AUTOSAR XML (schema 4-2-2)
package /STELLANTIS/EPT/ASWCs
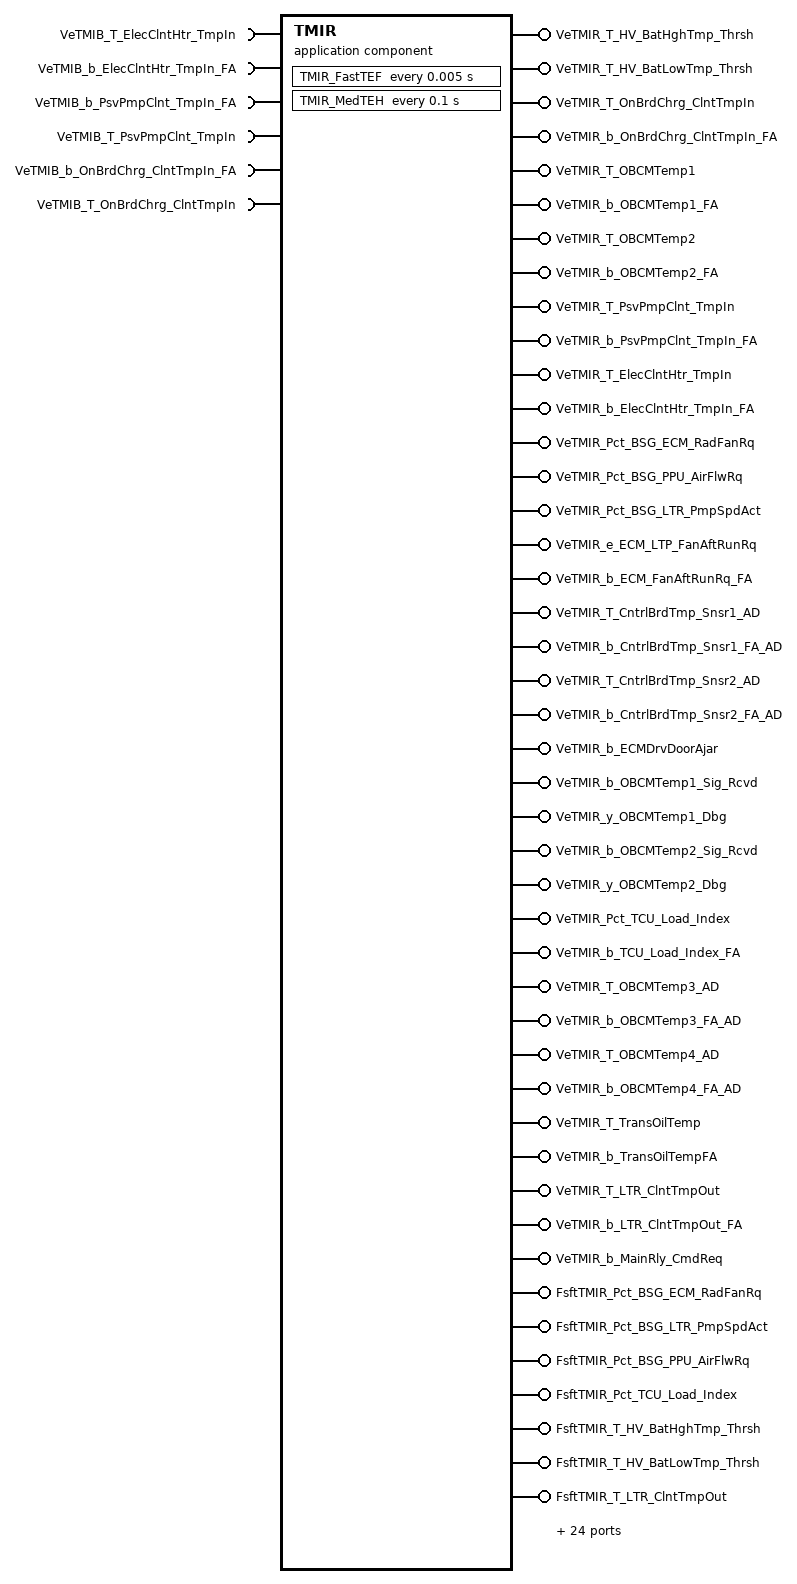
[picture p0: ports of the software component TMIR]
  application sw component type TMIR
    6 x require port, all with nonqueued-receiver-com-spec{data-element=Value, init-value=0}:
      VeTMIB_T_ElecClntHtr_TmpIn: required-interface=VeTMIB_T_ElecClntHtr_TmpIn
      VeTMIB_b_ElecClntHtr_TmpIn_FA: required-interface=VeTMIB_b_ElecClntHtr_TmpIn_FA
      VeTMIB_b_PsvPmpClnt_TmpIn_FA: required-interface=VeTMIB_b_PsvPmpClnt_TmpIn_FA
      VeTMIB_T_PsvPmpClnt_TmpIn: required-interface=VeTMIB_T_PsvPmpClnt_TmpIn
      VeTMIB_b_OnBrdChrg_ClntTmpIn_FA: required-interface=VeTMIB_b_OnBrdChrg_ClntTmpIn_FA
      VeTMIB_T_OnBrdChrg_ClntTmpIn: required-interface=VeTMIB_T_OnBrdChrg_ClntTmpIn
    74 x provide port:
      VeTMIR_T_HV_BatHghTmp_Thrsh: nonqueued-sender-com-spec{data-element=Value, init-value=0}, provided-interface=VeTMIR_T_HV_BatHghTmp_Thrsh
      VeTMIR_T_HV_BatLowTmp_Thrsh: nonqueued-sender-com-spec{data-element=Value, init-value=0}, provided-interface=VeTMIR_T_HV_BatLowTmp_Thrsh
      VeTMIR_T_OnBrdChrg_ClntTmpIn: nonqueued-sender-com-spec{data-element=Value, init-value=0}, provided-interface=VeTMIR_T_OnBrdChrg_ClntTmpIn
      VeTMIR_b_OnBrdChrg_ClntTmpIn_FA: nonqueued-sender-com-spec{data-element=Value, init-value=0}, provided-interface=VeTMIR_b_OnBrdChrg_ClntTmpIn_FA
      VeTMIR_T_OBCMTemp1: nonqueued-sender-com-spec{data-element=Value, init-value=0}, provided-interface=VeTMIR_T_OBCMTemp1
      VeTMIR_b_OBCMTemp1_FA: nonqueued-sender-com-spec{data-element=Value, init-value=0}, provided-interface=VeTMIR_b_OBCMTemp1_FA
      VeTMIR_T_OBCMTemp2: nonqueued-sender-com-spec{data-element=Value, init-value=0}, provided-interface=VeTMIR_T_OBCMTemp2
      VeTMIR_b_OBCMTemp2_FA: nonqueued-sender-com-spec{data-element=Value, init-value=0}, provided-interface=VeTMIR_b_OBCMTemp2_FA
      VeTMIR_T_PsvPmpClnt_TmpIn: nonqueued-sender-com-spec{data-element=Value, init-value=0}, provided-interface=VeTMIR_T_PsvPmpClnt_TmpIn
      VeTMIR_b_PsvPmpClnt_TmpIn_FA: nonqueued-sender-com-spec{data-element=Value, init-value=0}, provided-interface=VeTMIR_b_PsvPmpClnt_TmpIn_FA
      VeTMIR_T_ElecClntHtr_TmpIn: nonqueued-sender-com-spec{data-element=Value, init-value=0}, provided-interface=VeTMIR_T_ElecClntHtr_TmpIn
      VeTMIR_b_ElecClntHtr_TmpIn_FA: nonqueued-sender-com-spec{data-element=Value, init-value=0}, provided-interface=VeTMIR_b_ElecClntHtr_TmpIn_FA
      VeTMIR_Pct_BSG_ECM_RadFanRq: nonqueued-sender-com-spec{data-element=Value, init-value=0}, provided-interface=VeTMIR_Pct_BSG_ECM_RadFanRq
      VeTMIR_Pct_BSG_PPU_AirFlwRq: nonqueued-sender-com-spec{data-element=Value, init-value=0}, provided-interface=VeTMIR_Pct_BSG_PPU_AirFlwRq
      VeTMIR_Pct_BSG_LTR_PmpSpdAct: nonqueued-sender-com-spec{data-element=Value, init-value=0}, provided-interface=VeTMIR_Pct_BSG_LTR_PmpSpdAct
      VeTMIR_e_ECM_LTP_FanAftRunRq: nonqueued-sender-com-spec{data-element=Value, init-value=CeTMIR_e_No_AftRunRequest}, provided-interface=VeTMIR_e_ECM_LTP_FanAftRunRq
      VeTMIR_b_ECM_FanAftRunRq_FA: nonqueued-sender-com-spec{data-element=Value, init-value=0}, provided-interface=VeTMIR_b_ECM_FanAftRunRq_FA
      VeTMIR_T_CntrlBrdTmp_Snsr1_AD: nonqueued-sender-com-spec{data-element=Value, init-value=0}, provided-interface=VeTMIR_T_CntrlBrdTmp_Snsr1_AD
      VeTMIR_b_CntrlBrdTmp_Snsr1_FA_AD: nonqueued-sender-com-spec{data-element=Value, init-value=0}, provided-interface=VeTMIR_b_CntrlBrdTmp_Snsr1_FA_AD
      VeTMIR_T_CntrlBrdTmp_Snsr2_AD: nonqueued-sender-com-spec{data-element=Value, init-value=0}, provided-interface=VeTMIR_T_CntrlBrdTmp_Snsr2_AD
      VeTMIR_b_CntrlBrdTmp_Snsr2_FA_AD: nonqueued-sender-com-spec{data-element=Value, init-value=0}, provided-interface=VeTMIR_b_CntrlBrdTmp_Snsr2_FA_AD
      VeTMIR_b_ECMDrvDoorAjar: nonqueued-sender-com-spec{data-element=Value, init-value=0}, provided-interface=VeTMIR_b_ECMDrvDoorAjar
      VeTMIR_b_OBCMTemp1_Sig_Rcvd: nonqueued-sender-com-spec{data-element=Value, init-value=0}, provided-interface=VeTMIR_b_OBCMTemp1_Sig_Rcvd
      VeTMIR_y_OBCMTemp1_Dbg: nonqueued-sender-com-spec{data-element=Value, init-value=0}, provided-interface=VeTMIR_y_OBCMTemp1_Dbg
      VeTMIR_b_OBCMTemp2_Sig_Rcvd: nonqueued-sender-com-spec{data-element=Value, init-value=0}, provided-interface=VeTMIR_b_OBCMTemp2_Sig_Rcvd
      VeTMIR_y_OBCMTemp2_Dbg: nonqueued-sender-com-spec{data-element=Value, init-value=0}, provided-interface=VeTMIR_y_OBCMTemp2_Dbg
      VeTMIR_Pct_TCU_Load_Index: nonqueued-sender-com-spec{data-element=Value, init-value=0}, provided-interface=VeTMIR_Pct_TCU_Load_Index
      VeTMIR_b_TCU_Load_Index_FA: nonqueued-sender-com-spec{data-element=Value, init-value=0}, provided-interface=VeTMIR_b_TCU_Load_Index_FA
      VeTMIR_T_OBCMTemp3_AD: nonqueued-sender-com-spec{data-element=Value, init-value=0}, provided-interface=VeTMIR_T_OBCMTemp3_AD
      VeTMIR_b_OBCMTemp3_FA_AD: nonqueued-sender-com-spec{data-element=Value, init-value=0}, provided-interface=VeTMIR_b_OBCMTemp3_FA_AD
      VeTMIR_T_OBCMTemp4_AD: nonqueued-sender-com-spec{data-element=Value, init-value=0}, provided-interface=VeTMIR_T_OBCMTemp4_AD
      VeTMIR_b_OBCMTemp4_FA_AD: nonqueued-sender-com-spec{data-element=Value, init-value=0}, provided-interface=VeTMIR_b_OBCMTemp4_FA_AD
      VeTMIR_T_TransOilTemp: nonqueued-sender-com-spec{data-element=Value, init-value=0}, provided-interface=VeTMIR_T_TransOilTemp
      VeTMIR_b_TransOilTempFA: nonqueued-sender-com-spec{data-element=Value, init-value=0}, provided-interface=VeTMIR_b_TransOilTempFA
      VeTMIR_T_LTR_ClntTmpOut: nonqueued-sender-com-spec{data-element=Value, init-value=0}, provided-interface=VeTMIR_T_LTR_ClntTmpOut
      VeTMIR_b_LTR_ClntTmpOut_FA: nonqueued-sender-com-spec{data-element=Value, init-value=0}, provided-interface=VeTMIR_b_LTR_ClntTmpOut_FA
      VeTMIR_b_MainRly_CmdReq: nonqueued-sender-com-spec{data-element=Value, init-value=0}, provided-interface=VeTMIR_b_MainRly_CmdReq
      FsftTMIR_Pct_BSG_ECM_RadFanRq: server-com-spec=FsftTMIR_Pct_BSG_ECM_RadFanRq, provided-interface=FsftTMIR_Pct_BSG_ECM_RadFanRq
      FsftTMIR_Pct_BSG_LTR_PmpSpdAct: server-com-spec=FsftTMIR_Pct_BSG_LTR_PmpSpdAct, provided-interface=FsftTMIR_Pct_BSG_LTR_PmpSpdAct
      FsftTMIR_Pct_BSG_PPU_AirFlwRq: server-com-spec=FsftTMIR_Pct_BSG_PPU_AirFlwRq, provided-interface=FsftTMIR_Pct_BSG_PPU_AirFlwRq
      FsftTMIR_Pct_TCU_Load_Index: server-com-spec=FsftTMIR_Pct_TCU_Load_Index, provided-interface=FsftTMIR_Pct_TCU_Load_Index
      FsftTMIR_T_HV_BatHghTmp_Thrsh: server-com-spec=FsftTMIR_T_HV_BatHghTmp_Thrsh, provided-interface=FsftTMIR_T_HV_BatHghTmp_Thrsh
      FsftTMIR_T_HV_BatLowTmp_Thrsh: server-com-spec=FsftTMIR_T_HV_BatLowTmp_Thrsh, provided-interface=FsftTMIR_T_HV_BatLowTmp_Thrsh
      FsftTMIR_T_LTR_ClntTmpOut: server-com-spec=FsftTMIR_T_LTR_ClntTmpOut, provided-interface=FsftTMIR_T_LTR_ClntTmpOut
      FsftTMIR_T_OBCMTemp{1..4}: server-com-spec=FsftTMIR_T_OBCMTemp{1..4}, provided-interface=FsftTMIR_T_OBCMTemp{1..4}
      FsftTMIR_V_DISPLACEMENT: server-com-spec=FsftTMIR_V_DISPLACEMENT, provided-interface=FsftTMIR_V_DISPLACEMENT
      FsftTMIR_b_ECMDrvDoorAjar: server-com-spec=FsftTMIR_b_ECMDrvDoorAjar, provided-interface=FsftTMIR_b_ECMDrvDoorAjar
      FsftTMIR_e_ECM_LTP_FanAftRun_Rq: server-com-spec=FsftTMIR_e_ECM_LTP_FanAftRun_Rq, provided-interface=FsftTMIR_e_ECM_LTP_FanAftRun_Rq
      FsftTMIR_e_VC_VEH_LINE: server-com-spec=FsftTMIR_e_VC_VEH_LINE, provided-interface=FsftTMIR_e_VC_VEH_LINE
      PokeTMIR_Pct_BSG_ECM_RadFanRq: server-com-spec{operation=PokeTMIR_Pct_BSG_ECM_RadFanRq, queue-length=1}, provided-interface=PokeTMIR_Pct_BSG_ECM_RadFanRq
      PokeTMIR_Pct_BSG_LTR_PmpSpdAct: server-com-spec{operation=PokeTMIR_Pct_BSG_LTR_PmpSpdAct, queue-length=1}, provided-interface=PokeTMIR_Pct_BSG_LTR_PmpSpdAct
      PokeTMIR_Pct_BSG_PPU_AirFlwRq: server-com-spec{operation=PokeTMIR_Pct_BSG_PPU_AirFlwRq, queue-length=1}, provided-interface=PokeTMIR_Pct_BSG_PPU_AirFlwRq
      PokeTMIR_Pct_TCU_Load_Index: server-com-spec{operation=PokeTMIR_Pct_TCU_Load_Index, queue-length=1}, provided-interface=PokeTMIR_Pct_TCU_Load_Index
      PokeTMIR_T_HV_BatHghTmp_Thrsh: server-com-spec{operation=PokeTMIR_T_HV_BatHghTmp_Thrsh, queue-length=1}, provided-interface=PokeTMIR_T_HV_BatHghTmp_Thrsh
      PokeTMIR_T_HV_BatLowTmp_Thrsh: server-com-spec{operation=PokeTMIR_T_HV_BatLowTmp_Thrsh, queue-length=1}, provided-interface=PokeTMIR_T_HV_BatLowTmp_Thrsh
      PokeTMIR_T_LTR_ClntTmpOut: server-com-spec{operation=PokeTMIR_T_LTR_ClntTmpOut, queue-length=1}, provided-interface=PokeTMIR_T_LTR_ClntTmpOut
      PokeTMIR_T_OBCMTemp{1..4}: server-com-spec{operation=PokeTMIR_T_OBCMTemp{1..4}, queue-length=1}, provided-interface=PokeTMIR_T_OBCMTemp{1..4}
      PokeTMIR_T_PIM_CntrlBoardTmp1: server-com-spec{operation=PokeTMIR_T_PIM_CntrlBoardTmp1, queue-length=1}, provided-interface=PokeTMIR_T_PIM_CntrlBoardTmp1
      PokeTMIR_T_PIM_CntrlBoardTmp2: server-com-spec{operation=PokeTMIR_T_PIM_CntrlBoardTmp2, queue-length=1}, provided-interface=PokeTMIR_T_PIM_CntrlBoardTmp2
      PokeTMIR_T_TransOilTemp: server-com-spec{operation=PokeTMIR_T_TransOilTemp, queue-length=1}, provided-interface=PokeTMIR_T_TransOilTemp
      PokeTMIR_V_DISPLACEMENT: server-com-spec{operation=PokeTMIR_V_DISPLACEMENT, queue-length=1}, provided-interface=PokeTMIR_V_DISPLACEMENT
      PokeTMIR_b_MainRly_CmdReq: server-com-spec{operation=PokeTMIR_b_MainRly_CmdReq, queue-length=1}, provided-interface=PokeTMIR_b_MainRly_CmdReq
      PokeTMIR_e_ECMDrvDoorAjar: server-com-spec{operation=PokeTMIR_e_ECMDrvDoorAjar, queue-length=1}, provided-interface=PokeTMIR_e_ECMDrvDoorAjar
      PokeTMIR_e_ECM_LTP_FanAftRun_Rq: server-com-spec{operation=PokeTMIR_e_ECM_LTP_FanAftRun_Rq, queue-length=1}, provided-interface=PokeTMIR_e_ECM_LTP_FanAftRun_Rq
      PokeTMIR_e_VC_VEH_LINE: server-com-spec{operation=PokeTMIR_e_VC_VEH_LINE, queue-length=1}, provided-interface=PokeTMIR_e_VC_VEH_LINE
      TmotTMIR_b_ECMDrvDoorAjar: server-com-spec=TmotTMIR_b_ECMDrvDoorAjar, provided-interface=TmotTMIR_b_ECMDrvDoorAjar
      TmotTMIR_b_OBCMTemp1: server-com-spec=TmotTMIR_b_OBCMTemp1, provided-interface=TmotTMIR_b_OBCMTemp1
      TmotTMIR_b_OBCMTemp2: server-com-spec=TmotTMIR_b_OBCMTemp2, provided-interface=TmotTMIR_b_OBCMTemp2
    behavior IB_TMIR: data-type-mapping=msADTtoIDTMapping, handle-termination-and-restart=NO-SUPPORT
      timing event Event_FastTEF: start-on-event=TMIR_FastTEF, period=0.005
      timing event Event_MedTEH: start-on-event=TMIR_MedTEH, period=0.1
      37 x operation invoked event:
        Event_FsftTMIR_Pct_BSG_ECM_RadFanRq: start-on-event=FsftTMIR_Pct_BSG_ECM_RadFanRq, operation=FsftTMIR_Pct_BSG_ECM_RadFanRq.FsftTMIR_Pct_BSG_ECM_RadFanRq
        Event_FsftTMIR_Pct_BSG_LTR_PmpSpdAct: start-on-event=FsftTMIR_Pct_BSG_LTR_PmpSpdAct, operation=FsftTMIR_Pct_BSG_LTR_PmpSpdAct.FsftTMIR_Pct_BSG_LTR_PmpSpdAct
        Event_FsftTMIR_Pct_BSG_PPU_AirFlwRq: start-on-event=FsftTMIR_Pct_BSG_PPU_AirFlwRq, operation=FsftTMIR_Pct_BSG_PPU_AirFlwRq.FsftTMIR_Pct_BSG_PPU_AirFlwRq
        Event_FsftTMIR_Pct_TCU_Load_Index: start-on-event=FsftTMIR_Pct_TCU_Load_Index, operation=FsftTMIR_Pct_TCU_Load_Index.FsftTMIR_Pct_TCU_Load_Index
        Event_FsftTMIR_T_HV_BatHghTmp_Thrsh: start-on-event=FsftTMIR_T_HV_BatHghTmp_Thrsh, operation=FsftTMIR_T_HV_BatHghTmp_Thrsh.FsftTMIR_T_HV_BatHghTmp_Thrsh
        Event_FsftTMIR_T_HV_BatLowTmp_Thrsh: start-on-event=FsftTMIR_T_HV_BatLowTmp_Thrsh, operation=FsftTMIR_T_HV_BatLowTmp_Thrsh.FsftTMIR_T_HV_BatLowTmp_Thrsh
        Event_FsftTMIR_T_LTR_ClntTmpOut: start-on-event=FsftTMIR_T_LTR_ClntTmpOut, operation=FsftTMIR_T_LTR_ClntTmpOut.FsftTMIR_T_LTR_ClntTmpOut
        Event_FsftTMIR_T_OBCMTemp{1..4}: start-on-event=FsftTMIR_T_OBCMTemp{1..4}, operation=FsftTMIR_T_OBCMTemp{1..4}.FsftTMIR_T_OBCMTemp{1..4}
        Event_FsftTMIR_V_DISPLACEMENT: start-on-event=FsftTMIR_V_DISPLACEMENT, operation=FsftTMIR_V_DISPLACEMENT.FsftTMIR_V_DISPLACEMENT
        Event_FsftTMIR_b_ECMDrvDoorAjar: start-on-event=FsftTMIR_b_ECMDrvDoorAjar, operation=FsftTMIR_b_ECMDrvDoorAjar.FsftTMIR_b_ECMDrvDoorAjar
        Event_FsftTMIR_e_ECM_LTP_FanAftRun_Rq: start-on-event=FsftTMIR_e_ECM_LTP_FanAftRun_Rq, operation=FsftTMIR_e_ECM_LTP_FanAftRun_Rq.FsftTMIR_e_ECM_LTP_FanAftRun_Rq
        Event_FsftTMIR_e_VC_VEH_LINE: start-on-event=FsftTMIR_e_VC_VEH_LINE, operation=FsftTMIR_e_VC_VEH_LINE.FsftTMIR_e_VC_VEH_LINE
        Event_PokeTMIR_Pct_BSG_ECM_RadFanRq: start-on-event=PokeTMIR_Pct_BSG_ECM_RadFanRq, operation=PokeTMIR_Pct_BSG_ECM_RadFanRq.PokeTMIR_Pct_BSG_ECM_RadFanRq
        Event_PokeTMIR_Pct_BSG_LTR_PmpSpdAct: start-on-event=PokeTMIR_Pct_BSG_LTR_PmpSpdAct, operation=PokeTMIR_Pct_BSG_LTR_PmpSpdAct.PokeTMIR_Pct_BSG_LTR_PmpSpdAct
        Event_PokeTMIR_Pct_BSG_PPU_AirFlwRq: start-on-event=PokeTMIR_Pct_BSG_PPU_AirFlwRq, operation=PokeTMIR_Pct_BSG_PPU_AirFlwRq.PokeTMIR_Pct_BSG_PPU_AirFlwRq
        Event_PokeTMIR_Pct_TCU_Load_Index: start-on-event=PokeTMIR_Pct_TCU_Load_Index, operation=PokeTMIR_Pct_TCU_Load_Index.PokeTMIR_Pct_TCU_Load_Index
        Event_PokeTMIR_T_HV_BatHghTmp_Thrsh: start-on-event=PokeTMIR_T_HV_BatHghTmp_Thrsh, operation=PokeTMIR_T_HV_BatHghTmp_Thrsh.PokeTMIR_T_HV_BatHghTmp_Thrsh
        Event_PokeTMIR_T_HV_BatLowTmp_Thrsh: start-on-event=PokeTMIR_T_HV_BatLowTmp_Thrsh, operation=PokeTMIR_T_HV_BatLowTmp_Thrsh.PokeTMIR_T_HV_BatLowTmp_Thrsh
        Event_PokeTMIR_T_LTR_ClntTmpOut: start-on-event=PokeTMIR_T_LTR_ClntTmpOut, operation=PokeTMIR_T_LTR_ClntTmpOut.PokeTMIR_T_LTR_ClntTmpOut
        Event_PokeTMIR_T_OBCMTemp{1..4}: start-on-event=PokeTMIR_T_OBCMTemp{1..4}, operation=PokeTMIR_T_OBCMTemp{1..4}.PokeTMIR_T_OBCMTemp{1..4}
        Event_PokeTMIR_T_PIM_CntrlBoardTmp1: start-on-event=PokeTMIR_T_PIM_CntrlBoardTmp1, operation=PokeTMIR_T_PIM_CntrlBoardTmp1.PokeTMIR_T_PIM_CntrlBoardTmp1
        Event_PokeTMIR_T_PIM_CntrlBoardTmp2: start-on-event=PokeTMIR_T_PIM_CntrlBoardTmp2, operation=PokeTMIR_T_PIM_CntrlBoardTmp2.PokeTMIR_T_PIM_CntrlBoardTmp2
        Event_PokeTMIR_T_TransOilTemp: start-on-event=PokeTMIR_T_TransOilTemp, operation=PokeTMIR_T_TransOilTemp.PokeTMIR_T_TransOilTemp
        Event_PokeTMIR_V_DISPLACEMENT: start-on-event=PokeTMIR_V_DISPLACEMENT, operation=PokeTMIR_V_DISPLACEMENT.PokeTMIR_V_DISPLACEMENT
        Event_PokeTMIR_b_MainRly_CmdReq: start-on-event=PokeTMIR_b_MainRly_CmdReq, operation=PokeTMIR_b_MainRly_CmdReq.PokeTMIR_b_MainRly_CmdReq
        Event_PokeTMIR_e_ECMDrvDoorAjar: start-on-event=PokeTMIR_e_ECMDrvDoorAjar, operation=PokeTMIR_e_ECMDrvDoorAjar.PokeTMIR_e_ECMDrvDoorAjar
        Event_PokeTMIR_e_ECM_LTP_FanAftRun_Rq: start-on-event=PokeTMIR_e_ECM_LTP_FanAftRun_Rq, operation=PokeTMIR_e_ECM_LTP_FanAftRun_Rq.PokeTMIR_e_ECM_LTP_FanAftRun_Rq
        Event_PokeTMIR_e_VC_VEH_LINE: start-on-event=PokeTMIR_e_VC_VEH_LINE, operation=PokeTMIR_e_VC_VEH_LINE.PokeTMIR_e_VC_VEH_LINE
        Event_TmotTMIR_b_ECMDrvDoorAjar: start-on-event=TmotTMIR_b_ECMDrvDoorAjar, operation=TmotTMIR_b_ECMDrvDoorAjar.TmotTMIR_b_ECMDrvDoorAjar
        Event_TmotTMIR_b_OBCMTemp1: start-on-event=TmotTMIR_b_OBCMTemp1, operation=TmotTMIR_b_OBCMTemp1.TmotTMIR_b_OBCMTemp1
        Event_TmotTMIR_b_OBCMTemp2: start-on-event=TmotTMIR_b_OBCMTemp2, operation=TmotTMIR_b_OBCMTemp2.TmotTMIR_b_OBCMTemp2
      init event Event_TMIR_ac_Init: start-on-event=TMIR_ac_Init
      init event Event_PwrOn: start-on-event=TMIR_PwrOn
      explicit-inter-runnable-variables:
        29 x data, all with category=VALUE, sw-calibration-access=READ-ONLY:
          VeTMIR_T_HV_BatHghTmp_Thrsh_write_IRV: type=Float, init-value=0
          VeTMIR_T_HV_BatLowTmp_Thrsh_write_IRV: type=Float, init-value=0
          VeTMIR_T_OBCMTemp1_write_IRV: type=Float, init-value=0
          VeTMIR_b_OBCMTemp1FA_write_IRV: type=Boolean, init-value=0
          VeTMIR_T_OBCMTemp2_write_IRV: type=Float, init-value=0
          VeTMIR_b_OBCMTemp2FA_write_IRV: type=Boolean, init-value=0
          VeTMIR_T_PIM_CntrlBoardTmp1_write_IRV: type=Float, init-value=0
          VeTMIR_b_PIM_CntrlBoardTmp1FA_write_IRV: type=Boolean, init-value=0
          VeTMIR_T_PIM_CntrlBoardTmp2_write_IRV: type=Float, init-value=0
          VeTMIR_b_PIM_CntrlBoardTmp2FA_write_IRV: type=Boolean, init-value=0
          VeTMIR_b_OBCMTemp1_Sig_Rcvd_write_IRV: type=Boolean, init-value=0
          VeTMIR_y_Dbg_OBCMTemp1_write_IRV: type=UInt8, init-value=0
          VeTMIR_b_OBCMTemp2_Sig_Rcvd_write_IRV: type=Boolean, init-value=0
          VeTMIR_y_Dbg_OBCMTemp2_write_IRV: type=UInt8, init-value=0
          VeTMIR_Pct_TCU_Load_Index_write_IRV: type=Float, init-value=0
          VeTMIR_b_TCU_Load_IndexFA_write_IRV: type=Boolean, init-value=0
          VeTMIR_T_OBCMTemp3_write_IRV: type=Float, init-value=0
          VeTMIR_b_OBCMTemp3FA_write_IRV: type=Boolean, init-value=0
          VeTMIR_T_OBCMTemp4_write_IRV: type=Float, init-value=0
          VeTMIR_b_OBCMTemp4FA_write_IRV: type=Boolean, init-value=0
          VeTMIR_T_LTR_ClntTmpOut_write_IRV: type=Float, init-value=0
          VeTMIR_b_LTR_ClntTmpOutFA_write_IRV: type=Boolean, init-value=0
          VeTMIR_e_ECMDrvDoorAjar_write_IRV: type=TeTMIR_e_ECMDrvDrAjar, init-value=CeTMIR_e_DrvDoorClosed
          VeTMIR_b_MainRly_CmdReq_write_IRV: type=Boolean, init-value=0
          VeTMIR_Pct_BSG_ECM_RadFanRq_write_IRV: type=Float, init-value=0
          VeTMIR_Pct_BSG_PPU_AirFlwRq_write_IRV: type=Float, init-value=0
          VeTMIR_Pct_BSG_LTR_PmpSpdAct_write_IRV: type=Float, init-value=0
          VeTMIR_e_ECM_LTP_FanAftRun_Rq_write_IRV: type=TeTMIR_e_ECM_LTP_FanAftRunRq, init-value=CeTMIR_e_No_AftRunRequest
          VeTMIR_b_ECM_LTP_FanAftRun_RqFA_write_IRV: type=Boolean, init-value=0
      41 x runnable:
        TMIR_ac_Init
          data-send-points:
            access OUT_VeTMIR_e_ECM_LTP_FanAftRunRq_Value: accessed-variable=VeTMIR_e_ECM_LTP_FanAftRunRq.Value
        TMIR_PwrOn
          data-send-points:
            37 x access:
              OUT_VeTMIR_T_TransOilTemp_Value: accessed-variable=VeTMIR_T_TransOilTemp.Value
              OUT_VeTMIR_b_TransOilTempFA_Value: accessed-variable=VeTMIR_b_TransOilTempFA.Value
              OUT_VeTMIR_T_HV_BatHghTmp_Thrsh_Value: accessed-variable=VeTMIR_T_HV_BatHghTmp_Thrsh.Value
              OUT_VeTMIR_T_HV_BatLowTmp_Thrsh_Value: accessed-variable=VeTMIR_T_HV_BatLowTmp_Thrsh.Value
              OUT_VeTMIR_T_OnBrdChrg_ClntTmpIn_Value: accessed-variable=VeTMIR_T_OnBrdChrg_ClntTmpIn.Value
              OUT_VeTMIR_b_OnBrdChrg_ClntTmpIn_FA_Value: accessed-variable=VeTMIR_b_OnBrdChrg_ClntTmpIn_FA.Value
              OUT_VeTMIR_T_OBCMTemp1_Value: accessed-variable=VeTMIR_T_OBCMTemp1.Value
              OUT_VeTMIR_b_OBCMTemp1_FA_Value: accessed-variable=VeTMIR_b_OBCMTemp1_FA.Value
              OUT_VeTMIR_T_OBCMTemp2_Value: accessed-variable=VeTMIR_T_OBCMTemp2.Value
              OUT_VeTMIR_b_OBCMTemp2_FA_Value: accessed-variable=VeTMIR_b_OBCMTemp2_FA.Value
              OUT_VeTMIR_T_PsvPmpClnt_TmpIn_Value: accessed-variable=VeTMIR_T_PsvPmpClnt_TmpIn.Value
              OUT_VeTMIR_b_PsvPmpClnt_TmpIn_FA_Value: accessed-variable=VeTMIR_b_PsvPmpClnt_TmpIn_FA.Value
              OUT_VeTMIR_T_ElecClntHtr_TmpIn_Value: accessed-variable=VeTMIR_T_ElecClntHtr_TmpIn.Value
              OUT_VeTMIR_b_ElecClntHtr_TmpIn_FA_Value: accessed-variable=VeTMIR_b_ElecClntHtr_TmpIn_FA.Value
              OUT_VeTMIR_Pct_BSG_ECM_RadFanRq_Value: accessed-variable=VeTMIR_Pct_BSG_ECM_RadFanRq.Value
              OUT_VeTMIR_Pct_BSG_PPU_AirFlwRq_Value: accessed-variable=VeTMIR_Pct_BSG_PPU_AirFlwRq.Value
              OUT_VeTMIR_Pct_BSG_LTR_PmpSpdAct_Value: accessed-variable=VeTMIR_Pct_BSG_LTR_PmpSpdAct.Value
              OUT_VeTMIR_e_ECM_LTP_FanAftRunRq_Value: accessed-variable=VeTMIR_e_ECM_LTP_FanAftRunRq.Value
              OUT_VeTMIR_b_ECM_FanAftRunRq_FA_Value: accessed-variable=VeTMIR_b_ECM_FanAftRunRq_FA.Value
              OUT_VeTMIR_T_CntrlBrdTmp_Snsr1_AD_Value: accessed-variable=VeTMIR_T_CntrlBrdTmp_Snsr1_AD.Value
              OUT_VeTMIR_b_CntrlBrdTmp_Snsr1_FA_AD_Value: accessed-variable=VeTMIR_b_CntrlBrdTmp_Snsr1_FA_AD.Value
              OUT_VeTMIR_T_CntrlBrdTmp_Snsr2_AD_Value: accessed-variable=VeTMIR_T_CntrlBrdTmp_Snsr2_AD.Value
              OUT_VeTMIR_b_CntrlBrdTmp_Snsr2_FA_AD_Value: accessed-variable=VeTMIR_b_CntrlBrdTmp_Snsr2_FA_AD.Value
              OUT_VeTMIR_b_ECMDrvDoorAjar_Value: accessed-variable=VeTMIR_b_ECMDrvDoorAjar.Value
              OUT_VeTMIR_b_OBCMTemp1_Sig_Rcvd_Value: accessed-variable=VeTMIR_b_OBCMTemp1_Sig_Rcvd.Value
              OUT_VeTMIR_y_OBCMTemp1_Dbg_Value: accessed-variable=VeTMIR_y_OBCMTemp1_Dbg.Value
              OUT_VeTMIR_b_OBCMTemp2_Sig_Rcvd_Value: accessed-variable=VeTMIR_b_OBCMTemp2_Sig_Rcvd.Value
              OUT_VeTMIR_y_OBCMTemp2_Dbg_Value: accessed-variable=VeTMIR_y_OBCMTemp2_Dbg.Value
              OUT_VeTMIR_Pct_TCU_Load_Index_Value: accessed-variable=VeTMIR_Pct_TCU_Load_Index.Value
              OUT_VeTMIR_b_TCU_Load_Index_FA_Value: accessed-variable=VeTMIR_b_TCU_Load_Index_FA.Value
              OUT_VeTMIR_T_OBCMTemp3_AD_Value: accessed-variable=VeTMIR_T_OBCMTemp3_AD.Value
              OUT_VeTMIR_b_OBCMTemp3_FA_AD_Value: accessed-variable=VeTMIR_b_OBCMTemp3_FA_AD.Value
              OUT_VeTMIR_T_OBCMTemp4_AD_Value: accessed-variable=VeTMIR_T_OBCMTemp4_AD.Value
              OUT_VeTMIR_b_OBCMTemp4_FA_AD_Value: accessed-variable=VeTMIR_b_OBCMTemp4_FA_AD.Value
              OUT_VeTMIR_T_LTR_ClntTmpOut_Value: accessed-variable=VeTMIR_T_LTR_ClntTmpOut.Value
              OUT_VeTMIR_b_LTR_ClntTmpOut_FA_Value: accessed-variable=VeTMIR_b_LTR_ClntTmpOut_FA.Value
              OUT_VeTMIR_b_MainRly_CmdReq_Value: accessed-variable=VeTMIR_b_MainRly_CmdReq.Value
          written-local-variables:
            28 x access:
              WV_VeTMIR_Pct_BSG_ECM_RadFanRq_write_IRV: accessed-variable=VeTMIR_Pct_BSG_ECM_RadFanRq_write_IRV
              WV_VeTMIR_Pct_BSG_LTR_PmpSpdAct_write_IRV: accessed-variable=VeTMIR_Pct_BSG_LTR_PmpSpdAct_write_IRV
              WV_VeTMIR_Pct_BSG_PPU_AirFlwRq_write_IRV: accessed-variable=VeTMIR_Pct_BSG_PPU_AirFlwRq_write_IRV
              WV_VeTMIR_Pct_TCU_Load_Index_write_IRV: accessed-variable=VeTMIR_Pct_TCU_Load_Index_write_IRV
              WV_VeTMIR_T_HV_BatHghTmp_Thrsh_write_IRV: accessed-variable=VeTMIR_T_HV_BatHghTmp_Thrsh_write_IRV
              WV_VeTMIR_T_HV_BatLowTmp_Thrsh_write_IRV: accessed-variable=VeTMIR_T_HV_BatLowTmp_Thrsh_write_IRV
              WV_VeTMIR_T_LTR_ClntTmpOut_write_IRV: accessed-variable=VeTMIR_T_LTR_ClntTmpOut_write_IRV
              WV_VeTMIR_T_OBCMTemp{1..4}_write_IRV: accessed-variable=VeTMIR_T_OBCMTemp{1..4}_write_IRV
              WV_VeTMIR_T_PIM_CntrlBoardTmp1_write_IRV: accessed-variable=VeTMIR_T_PIM_CntrlBoardTmp1_write_IRV
              WV_VeTMIR_T_PIM_CntrlBoardTmp2_write_IRV: accessed-variable=VeTMIR_T_PIM_CntrlBoardTmp2_write_IRV
              WV_VeTMIR_b_LTR_ClntTmpOutFA_write_IRV: accessed-variable=VeTMIR_b_LTR_ClntTmpOutFA_write_IRV
              WV_VeTMIR_b_MainRly_CmdReq_write_IRV: accessed-variable=VeTMIR_b_MainRly_CmdReq_write_IRV
              WV_VeTMIR_b_OBCMTemp1FA_write_IRV: accessed-variable=VeTMIR_b_OBCMTemp1FA_write_IRV
              WV_VeTMIR_b_OBCMTemp1_Sig_Rcvd_write_IRV: accessed-variable=VeTMIR_b_OBCMTemp1_Sig_Rcvd_write_IRV
              WV_VeTMIR_b_OBCMTemp2FA_write_IRV: accessed-variable=VeTMIR_b_OBCMTemp2FA_write_IRV
              WV_VeTMIR_b_OBCMTemp2_Sig_Rcvd_write_IRV: accessed-variable=VeTMIR_b_OBCMTemp2_Sig_Rcvd_write_IRV
              WV_VeTMIR_b_OBCMTemp3FA_write_IRV: accessed-variable=VeTMIR_b_OBCMTemp3FA_write_IRV
              WV_VeTMIR_b_OBCMTemp4FA_write_IRV: accessed-variable=VeTMIR_b_OBCMTemp4FA_write_IRV
              WV_VeTMIR_b_PIM_CntrlBoardTmp1FA_write_IRV: accessed-variable=VeTMIR_b_PIM_CntrlBoardTmp1FA_write_IRV
              WV_VeTMIR_b_PIM_CntrlBoardTmp2FA_write_IRV: accessed-variable=VeTMIR_b_PIM_CntrlBoardTmp2FA_write_IRV
              WV_VeTMIR_b_TCU_Load_IndexFA_write_IRV: accessed-variable=VeTMIR_b_TCU_Load_IndexFA_write_IRV
              WV_VeTMIR_e_ECMDrvDoorAjar_write_IRV: accessed-variable=VeTMIR_e_ECMDrvDoorAjar_write_IRV
              WV_VeTMIR_e_ECM_LTP_FanAftRun_Rq_write_IRV: accessed-variable=VeTMIR_e_ECM_LTP_FanAftRun_Rq_write_IRV
              WV_VeTMIR_y_Dbg_OBCMTemp1_write_IRV: accessed-variable=VeTMIR_y_Dbg_OBCMTemp1_write_IRV
              WV_VeTMIR_y_Dbg_OBCMTemp2_write_IRV: accessed-variable=VeTMIR_y_Dbg_OBCMTemp2_write_IRV
        TMIR_FastTEF
          data-receive-point-by-arguments:
            access IN_VeTMIB_T_PsvPmpClnt_TmpIn_Value: accessed-variable=VeTMIB_T_PsvPmpClnt_TmpIn.Value
            access IN_VeTMIB_b_PsvPmpClnt_TmpIn_FA_Value: accessed-variable=VeTMIB_b_PsvPmpClnt_TmpIn_FA.Value
          data-send-points:
            4 x access:
              OUT_VeTMIR_T_HV_BatHghTmp_Thrsh_Value: accessed-variable=VeTMIR_T_HV_BatHghTmp_Thrsh.Value
              OUT_VeTMIR_T_HV_BatLowTmp_Thrsh_Value: accessed-variable=VeTMIR_T_HV_BatLowTmp_Thrsh.Value
              OUT_VeTMIR_T_PsvPmpClnt_TmpIn_Value: accessed-variable=VeTMIR_T_PsvPmpClnt_TmpIn.Value
              OUT_VeTMIR_b_PsvPmpClnt_TmpIn_FA_Value: accessed-variable=VeTMIR_b_PsvPmpClnt_TmpIn_FA.Value
          read-local-variables:
            access RV_VeTMIR_T_HV_BatHghTmp_Thrsh_write_IRV: accessed-variable=VeTMIR_T_HV_BatHghTmp_Thrsh_write_IRV
            access RV_VeTMIR_T_HV_BatLowTmp_Thrsh_write_IRV: accessed-variable=VeTMIR_T_HV_BatLowTmp_Thrsh_write_IRV
        TMIR_MedTEH
          data-receive-point-by-arguments:
            4 x access:
              IN_VeTMIB_T_ElecClntHtr_TmpIn_Value: accessed-variable=VeTMIB_T_ElecClntHtr_TmpIn.Value
              IN_VeTMIB_T_OnBrdChrg_ClntTmpIn_Value: accessed-variable=VeTMIB_T_OnBrdChrg_ClntTmpIn.Value
              IN_VeTMIB_b_ElecClntHtr_TmpIn_FA_Value: accessed-variable=VeTMIB_b_ElecClntHtr_TmpIn_FA.Value
              IN_VeTMIB_b_OnBrdChrg_ClntTmpIn_FA_Value: accessed-variable=VeTMIB_b_OnBrdChrg_ClntTmpIn_FA.Value
          data-send-points:
            31 x access:
              OUT_VeTMIR_T_OnBrdChrg_ClntTmpIn_Value: accessed-variable=VeTMIR_T_OnBrdChrg_ClntTmpIn.Value
              OUT_VeTMIR_b_OnBrdChrg_ClntTmpIn_FA_Value: accessed-variable=VeTMIR_b_OnBrdChrg_ClntTmpIn_FA.Value
              OUT_VeTMIR_T_OBCMTemp1_Value: accessed-variable=VeTMIR_T_OBCMTemp1.Value
              OUT_VeTMIR_b_OBCMTemp1_FA_Value: accessed-variable=VeTMIR_b_OBCMTemp1_FA.Value
              OUT_VeTMIR_T_OBCMTemp2_Value: accessed-variable=VeTMIR_T_OBCMTemp2.Value
              OUT_VeTMIR_b_OBCMTemp2_FA_Value: accessed-variable=VeTMIR_b_OBCMTemp2_FA.Value
              OUT_VeTMIR_T_ElecClntHtr_TmpIn_Value: accessed-variable=VeTMIR_T_ElecClntHtr_TmpIn.Value
              OUT_VeTMIR_b_ElecClntHtr_TmpIn_FA_Value: accessed-variable=VeTMIR_b_ElecClntHtr_TmpIn_FA.Value
              OUT_VeTMIR_T_CntrlBrdTmp_Snsr1_AD_Value: accessed-variable=VeTMIR_T_CntrlBrdTmp_Snsr1_AD.Value
              OUT_VeTMIR_b_CntrlBrdTmp_Snsr1_FA_AD_Value: accessed-variable=VeTMIR_b_CntrlBrdTmp_Snsr1_FA_AD.Value
              OUT_VeTMIR_T_CntrlBrdTmp_Snsr2_AD_Value: accessed-variable=VeTMIR_T_CntrlBrdTmp_Snsr2_AD.Value
              OUT_VeTMIR_b_CntrlBrdTmp_Snsr2_FA_AD_Value: accessed-variable=VeTMIR_b_CntrlBrdTmp_Snsr2_FA_AD.Value
              OUT_VeTMIR_b_OBCMTemp1_Sig_Rcvd_Value: accessed-variable=VeTMIR_b_OBCMTemp1_Sig_Rcvd.Value
              OUT_VeTMIR_y_OBCMTemp1_Dbg_Value: accessed-variable=VeTMIR_y_OBCMTemp1_Dbg.Value
              OUT_VeTMIR_b_OBCMTemp2_Sig_Rcvd_Value: accessed-variable=VeTMIR_b_OBCMTemp2_Sig_Rcvd.Value
              OUT_VeTMIR_y_OBCMTemp2_Dbg_Value: accessed-variable=VeTMIR_y_OBCMTemp2_Dbg.Value
              OUT_VeTMIR_Pct_TCU_Load_Index_Value: accessed-variable=VeTMIR_Pct_TCU_Load_Index.Value
              OUT_VeTMIR_b_TCU_Load_Index_FA_Value: accessed-variable=VeTMIR_b_TCU_Load_Index_FA.Value
              OUT_VeTMIR_T_OBCMTemp3_AD_Value: accessed-variable=VeTMIR_T_OBCMTemp3_AD.Value
              OUT_VeTMIR_b_OBCMTemp3_FA_AD_Value: accessed-variable=VeTMIR_b_OBCMTemp3_FA_AD.Value
              OUT_VeTMIR_T_OBCMTemp4_AD_Value: accessed-variable=VeTMIR_T_OBCMTemp4_AD.Value
              OUT_VeTMIR_b_OBCMTemp4_FA_AD_Value: accessed-variable=VeTMIR_b_OBCMTemp4_FA_AD.Value
              OUT_VeTMIR_T_LTR_ClntTmpOut_Value: accessed-variable=VeTMIR_T_LTR_ClntTmpOut.Value
              OUT_VeTMIR_b_LTR_ClntTmpOut_FA_Value: accessed-variable=VeTMIR_b_LTR_ClntTmpOut_FA.Value
              OUT_VeTMIR_b_ECMDrvDoorAjar_Value: accessed-variable=VeTMIR_b_ECMDrvDoorAjar.Value
              OUT_VeTMIR_b_MainRly_CmdReq_Value: accessed-variable=VeTMIR_b_MainRly_CmdReq.Value
              OUT_VeTMIR_Pct_BSG_ECM_RadFanRq_Value: accessed-variable=VeTMIR_Pct_BSG_ECM_RadFanRq.Value
              OUT_VeTMIR_Pct_BSG_PPU_AirFlwRq_Value: accessed-variable=VeTMIR_Pct_BSG_PPU_AirFlwRq.Value
              OUT_VeTMIR_Pct_BSG_LTR_PmpSpdAct_Value: accessed-variable=VeTMIR_Pct_BSG_LTR_PmpSpdAct.Value
              OUT_VeTMIR_e_ECM_LTP_FanAftRunRq_Value: accessed-variable=VeTMIR_e_ECM_LTP_FanAftRunRq.Value
              OUT_VeTMIR_b_ECM_FanAftRunRq_FA_Value: accessed-variable=VeTMIR_b_ECM_FanAftRunRq_FA.Value
          read-local-variables:
            27 x access:
              RV_VeTMIR_Pct_BSG_ECM_RadFanRq_write_IRV: accessed-variable=VeTMIR_Pct_BSG_ECM_RadFanRq_write_IRV
              RV_VeTMIR_Pct_BSG_LTR_PmpSpdAct_write_IRV: accessed-variable=VeTMIR_Pct_BSG_LTR_PmpSpdAct_write_IRV
              RV_VeTMIR_Pct_BSG_PPU_AirFlwRq_write_IRV: accessed-variable=VeTMIR_Pct_BSG_PPU_AirFlwRq_write_IRV
              RV_VeTMIR_Pct_TCU_Load_Index_write_IRV: accessed-variable=VeTMIR_Pct_TCU_Load_Index_write_IRV
              RV_VeTMIR_T_LTR_ClntTmpOut_write_IRV: accessed-variable=VeTMIR_T_LTR_ClntTmpOut_write_IRV
              RV_VeTMIR_T_OBCMTemp{1..4}_write_IRV: accessed-variable=VeTMIR_T_OBCMTemp{1..4}_write_IRV
              RV_VeTMIR_T_PIM_CntrlBoardTmp1_write_IRV: accessed-variable=VeTMIR_T_PIM_CntrlBoardTmp1_write_IRV
              RV_VeTMIR_T_PIM_CntrlBoardTmp2_write_IRV: accessed-variable=VeTMIR_T_PIM_CntrlBoardTmp2_write_IRV
              RV_VeTMIR_b_ECM_LTP_FanAftRun_RqFA_write_IRV: accessed-variable=VeTMIR_b_ECM_LTP_FanAftRun_RqFA_write_IRV
              RV_VeTMIR_b_LTR_ClntTmpOutFA_write_IRV: accessed-variable=VeTMIR_b_LTR_ClntTmpOutFA_write_IRV
              RV_VeTMIR_b_MainRly_CmdReq_write_IRV: accessed-variable=VeTMIR_b_MainRly_CmdReq_write_IRV
              RV_VeTMIR_b_OBCMTemp1FA_write_IRV: accessed-variable=VeTMIR_b_OBCMTemp1FA_write_IRV
              RV_VeTMIR_b_OBCMTemp1_Sig_Rcvd_write_IRV: accessed-variable=VeTMIR_b_OBCMTemp1_Sig_Rcvd_write_IRV
              RV_VeTMIR_b_OBCMTemp2FA_write_IRV: accessed-variable=VeTMIR_b_OBCMTemp2FA_write_IRV
              RV_VeTMIR_b_OBCMTemp2_Sig_Rcvd_write_IRV: accessed-variable=VeTMIR_b_OBCMTemp2_Sig_Rcvd_write_IRV
              RV_VeTMIR_b_OBCMTemp3FA_write_IRV: accessed-variable=VeTMIR_b_OBCMTemp3FA_write_IRV
              RV_VeTMIR_b_OBCMTemp4FA_write_IRV: accessed-variable=VeTMIR_b_OBCMTemp4FA_write_IRV
              RV_VeTMIR_b_PIM_CntrlBoardTmp1FA_write_IRV: accessed-variable=VeTMIR_b_PIM_CntrlBoardTmp1FA_write_IRV
              RV_VeTMIR_b_PIM_CntrlBoardTmp2FA_write_IRV: accessed-variable=VeTMIR_b_PIM_CntrlBoardTmp2FA_write_IRV
              RV_VeTMIR_b_TCU_Load_IndexFA_write_IRV: accessed-variable=VeTMIR_b_TCU_Load_IndexFA_write_IRV
              RV_VeTMIR_e_ECMDrvDoorAjar_write_IRV: accessed-variable=VeTMIR_e_ECMDrvDoorAjar_write_IRV
              RV_VeTMIR_e_ECM_LTP_FanAftRun_Rq_write_IRV: accessed-variable=VeTMIR_e_ECM_LTP_FanAftRun_Rq_write_IRV
              RV_VeTMIR_y_Dbg_OBCMTemp1_write_IRV: accessed-variable=VeTMIR_y_Dbg_OBCMTemp1_write_IRV
              RV_VeTMIR_y_Dbg_OBCMTemp2_write_IRV: accessed-variable=VeTMIR_y_Dbg_OBCMTemp2_write_IRV
        FsftTMIR_Pct_BSG_ECM_RadFanRq
        FsftTMIR_Pct_BSG_LTR_PmpSpdAct
        FsftTMIR_Pct_BSG_PPU_AirFlwRq
        FsftTMIR_Pct_TCU_Load_Index
          written-local-variables:
            access WV_VeTMIR_b_TCU_Load_IndexFA_write_IRV: accessed-variable=VeTMIR_b_TCU_Load_IndexFA_write_IRV
        FsftTMIR_T_HV_BatHghTmp_Thrsh
        FsftTMIR_T_HV_BatLowTmp_Thrsh
        FsftTMIR_T_LTR_ClntTmpOut
          written-local-variables:
            access WV_VeTMIR_b_LTR_ClntTmpOutFA_write_IRV: accessed-variable=VeTMIR_b_LTR_ClntTmpOutFA_write_IRV
        FsftTMIR_T_OBCMTemp1
          written-local-variables:
            access WV_VeTMIR_b_OBCMTemp1FA_write_IRV: accessed-variable=VeTMIR_b_OBCMTemp1FA_write_IRV
            access WV_VeTMIR_b_OBCMTemp1_Sig_Rcvd_write_IRV: accessed-variable=VeTMIR_b_OBCMTemp1_Sig_Rcvd_write_IRV
            access WV_VeTMIR_y_Dbg_OBCMTemp1_write_IRV: accessed-variable=VeTMIR_y_Dbg_OBCMTemp1_write_IRV
        FsftTMIR_T_OBCMTemp2
          written-local-variables:
            access WV_VeTMIR_b_OBCMTemp2FA_write_IRV: accessed-variable=VeTMIR_b_OBCMTemp2FA_write_IRV
            access WV_VeTMIR_b_OBCMTemp2_Sig_Rcvd_write_IRV: accessed-variable=VeTMIR_b_OBCMTemp2_Sig_Rcvd_write_IRV
            access WV_VeTMIR_y_Dbg_OBCMTemp2_write_IRV: accessed-variable=VeTMIR_y_Dbg_OBCMTemp2_write_IRV
        FsftTMIR_T_OBCMTemp3
          written-local-variables:
            access WV_VeTMIR_b_OBCMTemp3FA_write_IRV: accessed-variable=VeTMIR_b_OBCMTemp3FA_write_IRV
        FsftTMIR_T_OBCMTemp4
          written-local-variables:
            access WV_VeTMIR_b_OBCMTemp4FA_write_IRV: accessed-variable=VeTMIR_b_OBCMTemp4FA_write_IRV
        FsftTMIR_V_DISPLACEMENT
        FsftTMIR_b_ECMDrvDoorAjar
        FsftTMIR_e_ECM_LTP_FanAftRun_Rq
          written-local-variables:
            access WV_VeTMIR_b_ECM_LTP_FanAftRun_RqFA_write_IRV: accessed-variable=VeTMIR_b_ECM_LTP_FanAftRun_RqFA_write_IRV
        FsftTMIR_e_VC_VEH_LINE
        PokeTMIR_Pct_BSG_ECM_RadFanRq
          written-local-variables:
            access WV_VeTMIR_Pct_BSG_ECM_RadFanRq_write_IRV: accessed-variable=VeTMIR_Pct_BSG_ECM_RadFanRq_write_IRV
        PokeTMIR_Pct_BSG_LTR_PmpSpdAct
          written-local-variables:
            access WV_VeTMIR_Pct_BSG_LTR_PmpSpdAct_write_IRV: accessed-variable=VeTMIR_Pct_BSG_LTR_PmpSpdAct_write_IRV
        PokeTMIR_Pct_BSG_PPU_AirFlwRq
          written-local-variables:
            access WV_VeTMIR_Pct_BSG_PPU_AirFlwRq_write_IRV: accessed-variable=VeTMIR_Pct_BSG_PPU_AirFlwRq_write_IRV
        PokeTMIR_Pct_TCU_Load_Index
          written-local-variables:
            access WV_VeTMIR_Pct_TCU_Load_Index_write_IRV: accessed-variable=VeTMIR_Pct_TCU_Load_Index_write_IRV
            access WV_VeTMIR_b_TCU_Load_IndexFA_write_IRV: accessed-variable=VeTMIR_b_TCU_Load_IndexFA_write_IRV
        PokeTMIR_T_HV_BatHghTmp_Thrsh
          written-local-variables:
            access WV_VeTMIR_T_HV_BatHghTmp_Thrsh_write_IRV: accessed-variable=VeTMIR_T_HV_BatHghTmp_Thrsh_write_IRV
        PokeTMIR_T_HV_BatLowTmp_Thrsh
          written-local-variables:
            access WV_VeTMIR_T_HV_BatLowTmp_Thrsh_write_IRV: accessed-variable=VeTMIR_T_HV_BatLowTmp_Thrsh_write_IRV
        PokeTMIR_T_LTR_ClntTmpOut
          written-local-variables:
            access WV_VeTMIR_T_LTR_ClntTmpOut_write_IRV: accessed-variable=VeTMIR_T_LTR_ClntTmpOut_write_IRV
            access WV_VeTMIR_b_LTR_ClntTmpOutFA_write_IRV: accessed-variable=VeTMIR_b_LTR_ClntTmpOutFA_write_IRV
        PokeTMIR_T_OBCMTemp1
          written-local-variables:
            4 x access:
              WV_VeTMIR_T_OBCMTemp1_write_IRV: accessed-variable=VeTMIR_T_OBCMTemp1_write_IRV
              WV_VeTMIR_b_OBCMTemp1FA_write_IRV: accessed-variable=VeTMIR_b_OBCMTemp1FA_write_IRV
              WV_VeTMIR_b_OBCMTemp1_Sig_Rcvd_write_IRV: accessed-variable=VeTMIR_b_OBCMTemp1_Sig_Rcvd_write_IRV
              WV_VeTMIR_y_Dbg_OBCMTemp1_write_IRV: accessed-variable=VeTMIR_y_Dbg_OBCMTemp1_write_IRV
        PokeTMIR_T_OBCMTemp2
          written-local-variables:
            4 x access:
              WV_VeTMIR_T_OBCMTemp2_write_IRV: accessed-variable=VeTMIR_T_OBCMTemp2_write_IRV
              WV_VeTMIR_b_OBCMTemp2FA_write_IRV: accessed-variable=VeTMIR_b_OBCMTemp2FA_write_IRV
              WV_VeTMIR_b_OBCMTemp2_Sig_Rcvd_write_IRV: accessed-variable=VeTMIR_b_OBCMTemp2_Sig_Rcvd_write_IRV
              WV_VeTMIR_y_Dbg_OBCMTemp2_write_IRV: accessed-variable=VeTMIR_y_Dbg_OBCMTemp2_write_IRV
        PokeTMIR_T_OBCMTemp3
          written-local-variables:
            access WV_VeTMIR_T_OBCMTemp3_write_IRV: accessed-variable=VeTMIR_T_OBCMTemp3_write_IRV
            access WV_VeTMIR_b_OBCMTemp3FA_write_IRV: accessed-variable=VeTMIR_b_OBCMTemp3FA_write_IRV
        PokeTMIR_T_OBCMTemp4
          written-local-variables:
            access WV_VeTMIR_T_OBCMTemp4_write_IRV: accessed-variable=VeTMIR_T_OBCMTemp4_write_IRV
            access WV_VeTMIR_b_OBCMTemp4FA_write_IRV: accessed-variable=VeTMIR_b_OBCMTemp4FA_write_IRV
        PokeTMIR_T_PIM_CntrlBoardTmp1
          written-local-variables:
            access WV_VeTMIR_T_PIM_CntrlBoardTmp1_write_IRV: accessed-variable=VeTMIR_T_PIM_CntrlBoardTmp1_write_IRV
            access WV_VeTMIR_b_PIM_CntrlBoardTmp1FA_write_IRV: accessed-variable=VeTMIR_b_PIM_CntrlBoardTmp1FA_write_IRV
        PokeTMIR_T_PIM_CntrlBoardTmp2
          written-local-variables:
            access WV_VeTMIR_T_PIM_CntrlBoardTmp2_write_IRV: accessed-variable=VeTMIR_T_PIM_CntrlBoardTmp2_write_IRV
            access WV_VeTMIR_b_PIM_CntrlBoardTmp2FA_write_IRV: accessed-variable=VeTMIR_b_PIM_CntrlBoardTmp2FA_write_IRV
        PokeTMIR_T_TransOilTemp
          data-send-points:
            access OUT_VeTMIR_T_TransOilTemp_Value: accessed-variable=VeTMIR_T_TransOilTemp.Value
            access OUT_VeTMIR_b_TransOilTempFA_Value: accessed-variable=VeTMIR_b_TransOilTempFA.Value
        PokeTMIR_V_DISPLACEMENT
        PokeTMIR_b_MainRly_CmdReq
          written-local-variables:
            access WV_VeTMIR_b_MainRly_CmdReq_write_IRV: accessed-variable=VeTMIR_b_MainRly_CmdReq_write_IRV
        PokeTMIR_e_ECMDrvDoorAjar
          written-local-variables:
            access WV_VeTMIR_e_ECMDrvDoorAjar_write_IRV: accessed-variable=VeTMIR_e_ECMDrvDoorAjar_write_IRV
        PokeTMIR_e_ECM_LTP_FanAftRun_Rq
          written-local-variables:
            access WV_VeTMIR_b_ECM_LTP_FanAftRun_RqFA_write_IRV: accessed-variable=VeTMIR_b_ECM_LTP_FanAftRun_RqFA_write_IRV
            access WV_VeTMIR_e_ECM_LTP_FanAftRun_Rq_write_IRV: accessed-variable=VeTMIR_e_ECM_LTP_FanAftRun_Rq_write_IRV
        PokeTMIR_e_VC_VEH_LINE
        TmotTMIR_b_ECMDrvDoorAjar
        TmotTMIR_b_OBCMTemp1
          written-local-variables:
            access WV_VeTMIR_b_OBCMTemp1FA_write_IRV: accessed-variable=VeTMIR_b_OBCMTemp1FA_write_IRV
            access WV_VeTMIR_b_OBCMTemp1_Sig_Rcvd_write_IRV: accessed-variable=VeTMIR_b_OBCMTemp1_Sig_Rcvd_write_IRV
            access WV_VeTMIR_y_Dbg_OBCMTemp1_write_IRV: accessed-variable=VeTMIR_y_Dbg_OBCMTemp1_write_IRV
        TmotTMIR_b_OBCMTemp2
          written-local-variables:
            access WV_VeTMIR_b_OBCMTemp2FA_write_IRV: accessed-variable=VeTMIR_b_OBCMTemp2FA_write_IRV
            access WV_VeTMIR_b_OBCMTemp2_Sig_Rcvd_write_IRV: accessed-variable=VeTMIR_b_OBCMTemp2_Sig_Rcvd_write_IRV
            access WV_VeTMIR_y_Dbg_OBCMTemp2_write_IRV: accessed-variable=VeTMIR_y_Dbg_OBCMTemp2_write_IRV
      variation point proxy Variant_TMIR_1: category=CONDITION, condition-access=0
